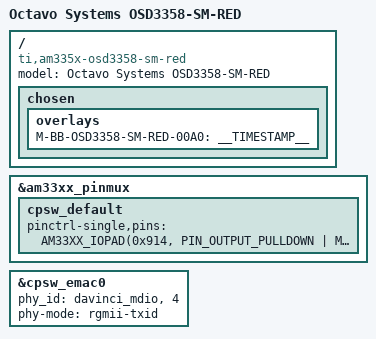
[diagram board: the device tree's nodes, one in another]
/*
 * Copyright (C) 2012 Texas Instruments Incorporated - http://www.ti.com/
 *
 * This program is free software; you can redistribute it and/or modify
 * it under the terms of the GNU General Public License version 2 as
 * published by the Free Software Foundation.
 */

/dts-v1/;
/plugin/;

#include <dt-bindings/gpio/gpio.h>
#include <dt-bindings/pinctrl/am33xx.h>
#include <dt-bindings/board/am335x-bbw-bbb-base.h>

/ {
	/*
	 * Helper to show loaded overlays under: /proc/device-tree/chosen/overlays/
	 */
	fragment@0 {
		target-path="/";
		__overlay__ {

			chosen {
				overlays {
					M-BB-OSD3358-SM-RED-00A0 = __TIMESTAMP__;
				};
			};
		};
	};

	fragment@1 {
		target-path="/";
		__overlay__ {
			model = "Octavo Systems OSD3358-SM-RED";
			compatible = "ti,am335x-osd3358-sm-red", "ti,am335x-bone-black", "ti,am335x-bone", "ti,am33xx";
		};
	};

	fragment@2 {
		target = <&am33xx_pinmux>;
		__overlay__ {

			cpsw_default {
				pinctrl-single,pins = <
					/* Slave 1 */
					AM33XX_IOPAD(0x914, PIN_OUTPUT_PULLDOWN | MUX_MODE2)	/* mii1_txen.rgmii1_tctl */
					AM33XX_IOPAD(0x918, PIN_INPUT_PULLDOWN | MUX_MODE2)		/* mii1_rxdv.rgmii1_rctl */
					AM33XX_IOPAD(0x91c, PIN_OUTPUT_PULLDOWN | MUX_MODE2)	/* mii1_txd3.rgmii1_txd3 */
					AM33XX_IOPAD(0x920, PIN_OUTPUT_PULLDOWN | MUX_MODE2)	/* mii1_txd2.rgmii1_txd2 */
					AM33XX_IOPAD(0x924, PIN_OUTPUT_PULLDOWN | MUX_MODE2)	/* mii1_txd1.rgmii1_txd1 */
					AM33XX_IOPAD(0x928, PIN_OUTPUT_PULLDOWN | MUX_MODE2)	/* mii1_txd0.rgmii1_txd0 */
					AM33XX_IOPAD(0x92c, PIN_OUTPUT_PULLDOWN | MUX_MODE2)	/* mii1_txclk.rgmii1_txclk */
					AM33XX_IOPAD(0x930, PIN_INPUT_PULLDOWN | MUX_MODE2)		/* mii1_rxclk.rgmii1_rxclk */
					AM33XX_IOPAD(0x934, PIN_INPUT_PULLDOWN | MUX_MODE2)		/* mii1_rxd3.rgmii1_rxd3 */
					AM33XX_IOPAD(0x938, PIN_INPUT_PULLDOWN | MUX_MODE2)		/* mii1_rxd2.rgmii1_rxd2 */
					AM33XX_IOPAD(0x93c, PIN_INPUT_PULLDOWN | MUX_MODE2)		/* mii1_rxd1.rgmii1_rxd1 */
					AM33XX_IOPAD(0x940, PIN_INPUT_PULLDOWN | MUX_MODE2)		/* mii1_rxd0.rgmii1_rxd0 */
				>;
			};
		};
	};

	fragment@3 {
		target = <&cpsw_emac0>;
		__overlay__ {
			phy_id = <&davinci_mdio>, <4>;
			phy-mode = "rgmii-txid";
		};
	};
};
